# ODS5010 register map
Vendor: OCS; Series: ODS5010; File version: 1.0
CPU: CM0plus r0p0, little endian, MPU, FPU, 4 interrupt priority bits
Registers are 32-bit, read-write, reset 0x0 unless marked. A register's access mark holds for its fields unless they carry their own. Offsets are from the block's base; lines under a group give offsets from that group; [hi:lo] are bit positions; {n}, {i} and the like mark numbered series; 'fields as' and 'values as' point back to an identical list; <NAME> marks a mode.

## Memory map
0x40006000 HWMATH size 0x2C — Hardware Mathematical Module, including square root, division, sine and cosine operation functions with status flags
0x40010C00 MCPWM size 0xD0 — Motor Control PWM
0x40012400 ADC size 0x9C — Analog-to-Digital Converter (ADC) Peripheral
0x48000000 GPIO_A size 0x90 — GPIO Port A
0x48000400 GPIO_B size 0x90 — GPIO Port B
0x48000800 GPIO_C size 0x90 — GPIO Port C

## GPIO_A — GPIO Port A
Base 0x48000000; register names take the prefix GPIO_A_
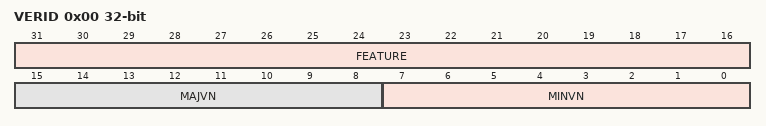
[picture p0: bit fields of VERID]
0x00 VERID ro — Version ID Register
  [31:16] FEATURE — Feature Identification
  [15:8] MAJVN — Major Version Number
  [7:0] MINVN — Minor Version Number
0x04 DR — Data Register
  [15:0] DR — Data Register Value
0x08 DRS — Data Set Register
  [15:0] DRS — Data Set Value
0x0C DRC — Data Clear Register
  [15:0] DRC — Data Clear Value
0x10 DRT — Data Toggle Register
  [15:0] DRT — Data Toggle Value
0x14 OES — Output Enable Set Register
  [15:0] OES — Output Enable Set Value
0x18 OEC — Output Enable Clear Register
  [15:0] OEC — Output Enable Clear Value
0x1C ITES — Interrupt Enable Set Register
  [15:0] ITES — Interrupt Enable Set Value
0x20 ITEC — Interrupt Enable Clear Register
  [15:0] ITEC — Interrupt Enable Clear Value
0x24 ITT0 — Interrupt Type for Pins 0-7
  [31:0] ITT0_7
0x28 ITT1 — Interrupt Type for Pins 8-15
  [31:0] ITT8_15
0x34 ITTC — Interrupt Type Control Register
  [15:0] ITTC — Interrupt Type Control Value
0x38 ITS — Interrupt Status Register
  [15:0] ITS — Interrupt Status Value
0x3C AF0 — Alternate Function for Pins 0-7
  [31:0] AF0_7
0x40 AF1 — Alternate Function for Pins 8-15
  [31:0] AF8_15
0x4C AFC — Alternate Function Control Register
  [15:0] AFC — Alternate Function Control Value
0x50 ANA — Analog Control Register
  [15:0] ANA — Analog Control Value
0x54 ANAC — Analog Control Configuration Register
  [15:0] ANAC — Analog Control Configuration Value
0x58 PU — Pull-up Register
  [15:0] PU — Pull-up Control Value
0x5C SPU — Strong Pull-up Register
  [15:0] SPU — Strong Pull-up Control Value
0x60 PUC — Pull-up Control Register
  [15:0] PUC — Pull-up Control Configuration Value
0x64 PD — Pull-down Register
  [15:0] PD — Pull-down Control Value
0x68 PDC — Pull-down Control Register
  [15:0] PDC — Pull-down Control Configuration Value
0x6C DRVS0 — Drive Strength for Pins 0-7
  [31:0] DRVS0_7
0x70 DRVS1 — Drive Strength for Pins 8-15
  [31:0] DRVS8_15
0x7C DRVC — Drive Strength Control Register
  [15:0] DRVC — Drive Strength Control Value
0x80 SLS — Slew Rate Set Register
  [15:0] SL — Slew Rate Set Value
0x84 SLC — Slew Rate Control Register
  [15:0] SLC — Slew Rate Control Value
0x88 STS — Schmitt Trigger Set Register
  [15:0] ST — Schmitt Trigger Set Value
0x8C STC — Schmitt Trigger Control Register
  [15:0] STC — Schmitt Trigger Control Value

## GPIO_B — GPIO Port B
Base 0x48000400; register names take the prefix GPIO_B_
Registers as GPIO_A.

## GPIO_C — GPIO Port C
Base 0x48000800; register names take the prefix GPIO_C_
Registers as GPIO_A.

## HWMATH — Hardware Mathematical Module, including square root, division, sine and cosine operation functions with status flags
Base 0x40006000; register names take the prefix HWMATH_
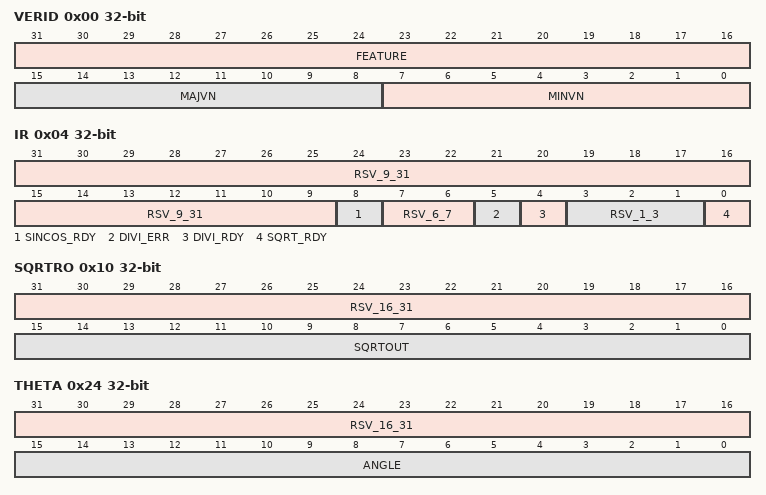
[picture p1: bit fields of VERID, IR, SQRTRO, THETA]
0x00 VERID — Version Identification Register, stores module version and feature information
  [31:16] FEATURE — Feature Identification Bit, indicates the operation functions supported by the module
  [15:8] MAJVN — Major Version Number
  [7:0] MINVN — Minor Version Number
0x04 IR — Interrupt Request Register, contains operation status flags and reserved bits
  [31:9] RSV_9_31 — Reserved Bits, no actual function
  [8] SINCOS_RDY — Sine/Cosine Operation Ready Flag, 1 indicates operation completed
  [7:6] RSV_6_7 — Reserved Bits, no actual function
  [5] DIVI_ERR — Division Operation Error Flag, 1 indicates division by zero or other errors
  [4] DIVI_RDY — Division Operation Ready Flag, 1 indicates operation completed
  [3:1] RSV_1_3 — Reserved Bits, no actual function
  [0] SQRT_RDY — Square Root Operation Ready Flag, 1 indicates operation completed
0x08 IE — Interrupt Enable Register (Reserved Bits)
  [31:0] RSV — Reserved Bits, no actual function
0x0C SQRTRI — Square Root Operation Input Register, stores 32-bit data to be square-rooted
  [31:0] SQRTIN — Square Root Input Data
0x10 SQRTRO — Square Root Operation Result Output Register
  [31:16] RSV_16_31 — Reserved Bits
  [15:0] SQRTOUT — Square Root Operation Result (16-bit valid data)
0x14 DIVIDE — Division Operation Dividend Register
  [31:0] DIVIDE — Division Operation Dividend
0x18 DIVIDS — Division Operation Divisor Register
  [31:0] DIVIDS — Division Operation Divisor
0x1C QUOTI — Division Operation Quotient Register
  [31:0] QUOTI — Division Operation Quotient Result
0x20 REMAIN — Division Operation Remainder Register
  [31:0] REMAIN — Division Operation Remainder Result
0x24 THETA — Sine/Cosine Operation Angle Input Register
  [31:16] RSV_16_31 — Reserved Bits
  [15:0] ANGLE — Input Angle Value (16-bit valid data)
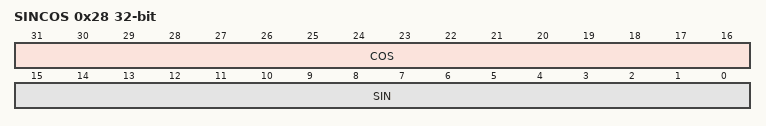
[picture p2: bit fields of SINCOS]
0x28 SINCOS — Sine/Cosine Operation Result Output Register
  [31:16] COS — Cosine Operation Result (16-bit valid data)
  [15:0] SIN — Sine Operation Result (16-bit valid data)
